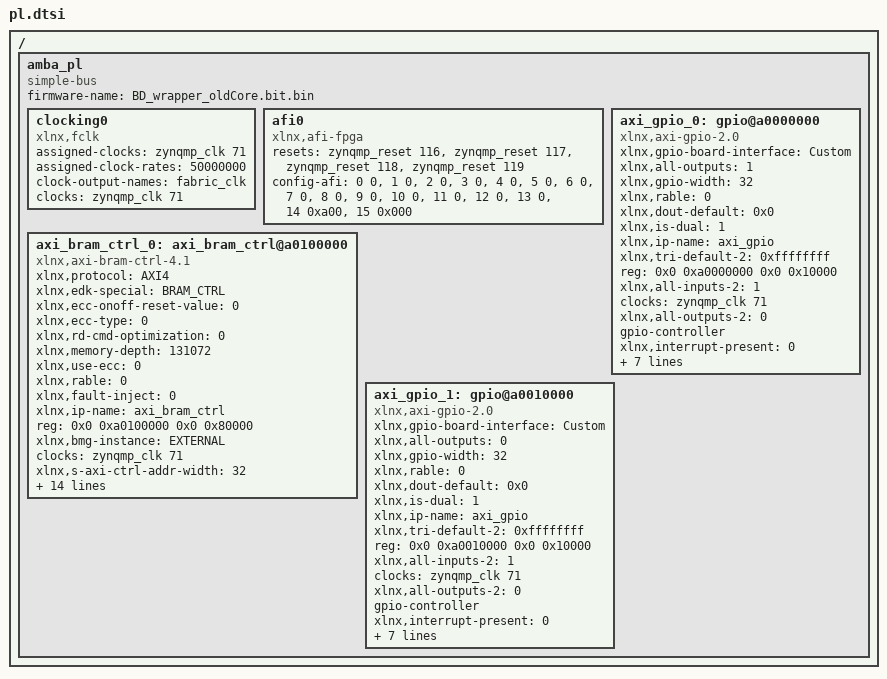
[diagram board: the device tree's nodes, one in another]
/ {
	amba_pl: amba_pl {
		ranges;
		compatible = "simple-bus";
		#address-cells = <2>;
		#size-cells = <2>;
		firmware-name = "BD_wrapper_oldCore.bit.bin";
		clocking0: clocking0 {
			compatible = "xlnx,fclk";
			status = "okay";
			assigned-clocks = <&zynqmp_clk 71>;
			assigned-clock-rates = <50000000>;
			#clock-cells = <0>;
			clock-output-names = "fabric_clk";
			clocks = <&zynqmp_clk 71>;
		};
		afi0: afi0 {
			status = "okay";
			compatible = "xlnx,afi-fpga";
			resets = <&zynqmp_reset 116>, <&zynqmp_reset 117>, <&zynqmp_reset 118>, <&zynqmp_reset 119>;
			config-afi = < 0 0>, <1 0>, <2 0>, <3 0>, <4 0>, <5 0>, <6 0>, <7 0>, <8 0>, <9 0>, <10 0>, <11 0>, <12 0>, <13 0>, <14 0xa00>, <15 0x000>;
		};
		axi_bram_ctrl_0: axi_bram_ctrl@a0100000 {
			xlnx,protocol = "AXI4";
			xlnx,edk-special = "BRAM_CTRL";
			compatible = "xlnx,axi-bram-ctrl-4.1";
			xlnx,ecc-onoff-reset-value = <0>;
			xlnx,ecc-type = <0>;
			xlnx,rd-cmd-optimization = <0>;
			xlnx,memory-depth = <131072>;
			xlnx,use-ecc = <0>;
			xlnx,rable = <0>;
			xlnx,fault-inject = <0>;
			xlnx,ip-name = "axi_bram_ctrl";
			reg = <0x0 0xa0100000 0x0 0x80000>;
			xlnx,bmg-instance = "EXTERNAL";
			clocks = <&zynqmp_clk 71>;
			xlnx,s-axi-ctrl-addr-width = <32>;
			xlnx,read-latency = <1>;
			xlnx,id-width = <0>;
			xlnx,s-axi-supports-narrow-burst = <0>;
			xlnx,supports-narrow-burst = <0>;
			xlnx,single-port-bram = <1>;
			xlnx,ecc = <0>;
			xlnx,edk-iptype = "PERIPHERAL";
			status = "okay";
			clock-names = "s_axi_aclk";
			xlnx,data-width = <32>;
			xlnx,bram-addr-width = <17>;
			xlnx,bram-inst-mode = "EXTERNAL";
			xlnx,s-axi-ctrl-data-width = <32>;
			xlnx,mem-depth = <131072>;
			xlnx,s-axi-id-width = <1>;
			xlnx,name = "axi_bram_ctrl_0";
		};
		axi_gpio_0: gpio@a0000000 {
			xlnx,gpio-board-interface = "Custom";
			compatible = "xlnx,axi-gpio-2.0" , "xlnx,xps-gpio-1.00.a";
			xlnx,all-outputs = <1>;
			#gpio-cells = <2>;
			xlnx,gpio-width = <32>;
			xlnx,rable = <0>;
			xlnx,dout-default = <0x0>;
			xlnx,is-dual = <1>;
			xlnx,ip-name = "axi_gpio";
			xlnx,tri-default-2 = <0xffffffff>;
			reg = <0x0 0xa0000000 0x0 0x10000>;
			xlnx,all-inputs-2 = <1>;
			clocks = <&zynqmp_clk 71>;
			xlnx,all-outputs-2 = <0>;
			gpio-controller;
			xlnx,interrupt-present = <0>;
			xlnx,gpio2-board-interface = "Custom";
			xlnx,edk-iptype = "PERIPHERAL";
			xlnx,dout-default-2 = <0x0>;
			status = "okay";
			xlnx,gpio2-width = <32>;
			clock-names = "s_axi_aclk";
			xlnx,tri-default = <0xffffffff>;
			xlnx,name = "axi_gpio_0";
			xlnx,all-inputs = <0>;
		};
		axi_gpio_1: gpio@a0010000 {
			xlnx,gpio-board-interface = "Custom";
			compatible = "xlnx,axi-gpio-2.0" , "xlnx,xps-gpio-1.00.a";
			xlnx,all-outputs = <0>;
			#gpio-cells = <2>;
			xlnx,gpio-width = <32>;
			xlnx,rable = <0>;
			xlnx,dout-default = <0x0>;
			xlnx,is-dual = <1>;
			xlnx,ip-name = "axi_gpio";
			xlnx,tri-default-2 = <0xffffffff>;
			reg = <0x0 0xa0010000 0x0 0x10000>;
			xlnx,all-inputs-2 = <1>;
			clocks = <&zynqmp_clk 71>;
			xlnx,all-outputs-2 = <0>;
			gpio-controller;
			xlnx,interrupt-present = <0>;
			xlnx,gpio2-board-interface = "Custom";
			xlnx,edk-iptype = "PERIPHERAL";
			xlnx,dout-default-2 = <0x0>;
			status = "okay";
			xlnx,gpio2-width = <32>;
			clock-names = "s_axi_aclk";
			xlnx,tri-default = <0xffffffff>;
			xlnx,name = "axi_gpio_1";
			xlnx,all-inputs = <1>;
		};
	};
};
